# nrf9120_modem register map
Vendor: Nordic Semiconductor; Series: nrf91; File version: 1
CPU: CM4 r0p1, little endian, MPU, FPU, 3 interrupt priority bits
Registers are 32-bit, read-write, reset 0x0 unless marked. A register's access mark holds for its fields unless they carry their own. Offsets are from the block's base; [hi:lo] are bit positions; lines under a group give offsets from that group; {n}, {i} and the like mark numbered series; 'fields as' and 'values as' point back to an identical list.

## FICR_NS — Factory Information Configuration Registers
Base 0x00FF0000
0x100 TESTSTATUS ro reset 0xFFFFFFFF — Code memory test status. Will be set during production test.
0x104 CPTEST0 ro reset 0xFFFFFFFF — Result from Circuit Probe test
  [31:0] CP1
0x108 CPTEST00 ro reset 0xFFFFFFFF — Result from Circuit Probe test
  [31:0] CP2
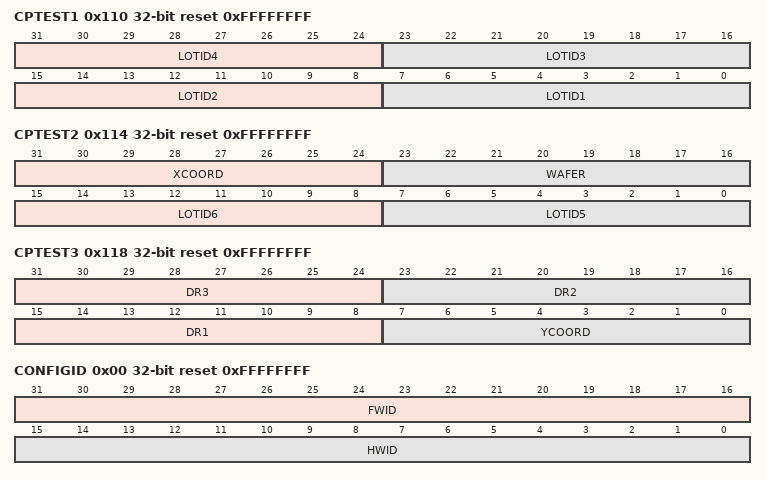
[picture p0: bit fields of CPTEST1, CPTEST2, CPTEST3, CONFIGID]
0x110 CPTEST1 ro reset 0xFFFFFFFF — Result from Circuit Probe test
  [31:24] LOTID4 — 4th ascii byte of Lot ID character
  [23:16] LOTID3 — 3rd ascii byte of Lot ID character
  [15:8] LOTID2 — 2nd ascii byte of Lot ID character
  [7:0] LOTID1 — 1st ascii byte of Lot ID character
0x114 CPTEST2 ro reset 0xFFFFFFFF — Result from Circuit Probe test
  [31:24] XCOORD — Device X-coordinate, always >=0, offset so that the leftmost value on wafer is 0
  [23:16] WAFER — Wafer number, 1 byte integer
  [15:8] LOTID6 — 6th ascii byte of Lot ID character
  [7:0] LOTID5 — 5th ascii byte of Lot ID character
0x118 CPTEST3 ro reset 0xFFFFFFFF — Result from Circuit Probe test
  [31:24] DR3 — Data Retention (DR) flag
  [23:16] DR2 — Data Retention (DR) flag
  [15:8] DR1 — Data Retention (DR) flag
  [7:0] YCOORD — Device Y-coordinate, always >=0, offset so that the bottom value on wafer is 0
0x11C CPTEST4 ro reset 0xFFFFFFFF — Result from Circuit Probe test
  [7:0] DR4 — Data Retention (DR) flag
{0x10C+4i} CPTEST{i} ro reset 0xFFFFFFFF (i=5..8) — Result from Circuit Probe test, flash repair information
  [31:0] CPTEST{i} — flash repair information
0x200 INFO group — Device info
  0x00 CONFIGID ro reset 0xFFFFFFFF — Configuration identifier
    [31:16] FWID — Deprecated field - Identification number for the FW that is pre-loaded into the chip
    [15:0] HWID — Identification number for the HW
  {0x4+4j} DEVICEID[{j}] (j=0..1) ro reset 0xFFFFFFFF — Description collection: Device identifier
    [31:0] DEVICEID — 64 bit unique device identifier
  0x0C PART ro reset 0x52832 — Part code
    [31:0] PART
      0xFFFFFFFF=Unspecified
  0x10 VARIANT ro reset 0x41414142 — Part Variant, Hardware version and Production configuration
    [31:0] VARIANT — Part Variant, Hardware version and Production configuration, encoded as ASCII
      0xFFFFFFFF=Unspecified
  0x14 PACKAGE ro reset 0x2000 — Package option
    [31:0] PACKAGE
      0xFFFFFFFF=Unspecified
  0x18 RAM ro reset 0x40 — RAM variant
    [31:0] RAM
      0xFFFFFFFF=Unspecified
  0x1C FLASH ro reset 0x200 — Flash variant
    [31:0] FLASH
      0xFFFFFFFF=Unspecified
  0x20 CODEPAGESIZE ro reset 0xFFFFFFFF — Code memory page size
  0x24 CODESIZE ro reset 0xFFFFFFFF — Code memory size
    [31:0] CODESIZE — Code memory size in number of pages
  0x28 DEVICETYPE ro reset 0xFFFFFFFF
    [31:0] DEVICETYPE
      0=Die (Device is an physical DIE); 0xFFFFFFFF=FPGA (Device is an FPGA)
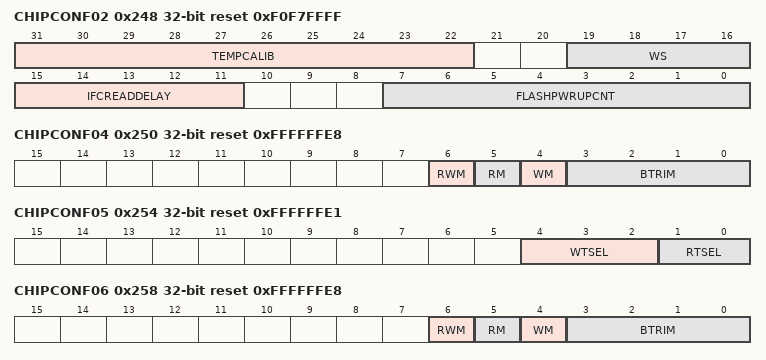
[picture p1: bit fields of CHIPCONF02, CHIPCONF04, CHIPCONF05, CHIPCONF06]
0x248 CHIPCONF02 ro reset 0xF0F7FFFF — Miscellaneous modem HW configuration. Will be set during production test.
  [31:22] TEMPCALIB — TEMP module calibration value (default value for TEMP->CALIB)
  [19:16] WS — wait-states (excluding the cache controller) for I-Code flash access, D-Code has one more wait-state.
    {v}={v}WS ({v} wait-state in total for I-Code ({v+1} for D-Code)) (v=1..15)
  [15:11] IFCREADDELAY — number of cycles before Information Configuration Registers can be read
  [7:0] FLASHPWRUPCNT — Number of successful FLASHPWRUPn read cycles when powering up flash. After chip power up, the NVMC controller reads FLASHPWRUPn for 7 us.
0x24C CHIPCONF03 ro reset 0xFFFFFFF0 — Miscellaneous modem HW configuration.
  [3:0] RAMWAITSTATE — Modem M4 RAM wait state configuration, into a modem secure control register.
0x250 CHIPCONF04 reset 0xFFFFFFE8 — MODEM M4 VMC SRAMTRIM values
  [6] RWM — Read/Write Margin Adjustment
    0=Disabled; 1=Enabled
  [5] RM — Read Margin Adjustment
    0=Disabled; 1=Enabled
  [4] WM — Write Margin Adjustment
    0=Disabled; 1=Enabled
  [3:0] BTRIM — Source Bias Trim Adjustment for retention
0x254 CHIPCONF05 reset 0xFFFFFFE1 — MODEM M4 VMC RamSSNonRetTSel timing control values for TSMC RAMs
  [4:2] WTSEL — Write cycle timing selection
  [1:0] RTSEL — Read cycle timing selection
0x258 CHIPCONF06 reset 0xFFFFFFE8 — MODEM DSP SRAMTRIM values
  fields as CHIPCONF04
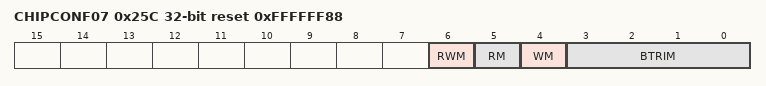
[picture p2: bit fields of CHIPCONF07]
0x25C CHIPCONF07 reset 0xFFFFFF88 — MODEM RF VMC SRAMTRIM values
  fields as CHIPCONF04
0x280 FLASHPWRUP0 ro reset 0xAAAAAAAA — Power-up pattern for flash
0x284 FLASHPWRUP1 ro reset 0xAAAAAAAA — Power-up pattern for flash
{0x800+4i} PRODTEST[{i}] (i=0..2) ro reset 0xFFFFFFFF — Description collection: Production test control n
  [31:0] PRODTEST — Production test control (majority vote done for each bit over all three fields to get the used value)
    0xBB42319F=Done (Production tests done); 0xFFFFFFFF=NotDone (Production tests not done, SoC is in Virgin mode (with any other value than 0xBB42319F))

## Notices in the file
Copyright (c) 2016, Nordic Semiconductor ASA
All rights reserved.
Redistribution and use in source and binary forms, with or without
modification, are permitted provided that the following conditions are met:
Redistributions of source code must retain the above copyright notice, this
list of conditions and the following disclaimer.
Redistributions in binary form must reproduce the above copyright notice,
this list of conditions and the following disclaimer in the documentation
and/or other materials provided with the distribution.
Neither the name of Nordic Semiconductor ASA nor the names of its
contributors may be used to endorse or promote products derived from
this software without specific prior written permission.
THIS SOFTWARE IS PROVIDED BY THE COPYRIGHT HOLDERS AND CONTRIBUTORS "AS IS"
AND ANY EXPRESS OR IMPLIED WARRANTIES, INCLUDING, BUT NOT LIMITED TO, THE
IMPLIED WARRANTIES OF MERCHANTABILITY AND FITNESS FOR A PARTICULAR PURPOSE ARE
DISCLAIMED. IN NO EVENT SHALL THE COPYRIGHT HOLDER OR CONTRIBUTORS BE LIABLE
FOR ANY DIRECT, INDIRECT, INCIDENTAL, SPECIAL, EXEMPLARY, OR CONSEQUENTIAL
DAMAGES (INCLUDING, BUT NOT LIMITED TO, PROCUREMENT OF SUBSTITUTE GOODS OR
SERVICES; LOSS OF USE, DATA, OR PROFITS; OR BUSINESS INTERRUPTION) HOWEVER
CAUSED AND ON ANY THEORY OF LIABILITY, WHETHER IN CONTRACT, STRICT LIABILITY,
OR TORT (INCLUDING NEGLIGENCE OR OTHERWISE) ARISING IN ANY WAY OUT OF THE USE
OF THIS SOFTWARE, EVEN IF ADVISED OF THE POSSIBILITY OF SUCH DAMAGE.
